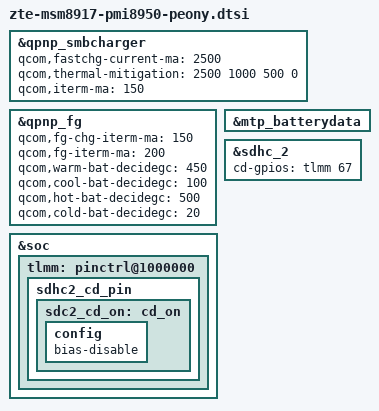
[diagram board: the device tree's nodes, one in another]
/*
 * Copyright (c) 2016, The Linux Foundation. All rights reserved.
 *
 * This program is free software; you can redistribute it and/or modify
 * it under the terms of the GNU General Public License version 2 and
 * only version 2 as published by the Free Software Foundation.
 *
 * This program is distributed in the hope that it will be useful,
 * but WITHOUT ANY WARRANTY; without even the implied warranty of
 * MERCHANTABILITY or FITNESS FOR A PARTICULAR PURPOSE.  See the
 * GNU General Public License for more details.
 */

/*
* device tree for zte crinum board
*/

#include "zte-msm8917-camera-sensor-peony.dtsi"
#include "touch-key-backlight-peony.dtsi"

&qpnp_smbcharger {
	qcom,fastchg-current-ma = <2500>;
	qcom,thermal-mitigation = <2500 1000 500 0>;
	qcom,iterm-ma = <150>;
};

&qpnp_fg {
	qcom,fg-chg-iterm-ma = <150>;
	qcom,fg-iterm-ma = <200>;
	qcom,warm-bat-decidegc = <450>;
	qcom,cool-bat-decidegc = <100>;
	qcom,hot-bat-decidegc  = <500>;
	qcom,cold-bat-decidegc = <20>;
};

&mtp_batterydata {
	#include "../zte_P817a22cos_3320mAh.dtsi"
	#include "../zte_p817a22_3140mah.dtsi"
};

&sdhc_2 {
	cd-gpios = <&tlmm 67 0x0>;
};
&soc {
	tlmm: pinctrl@1000000 {
		sdhc2_cd_pin {
			sdc2_cd_on: cd_on {
				config {
					/delete-property/bias-pull-up;
					bias-disable;
				};
			};
		};
	};
};
